# STM32WBA52 register map
File version: 1.3
CPU: CM33 r0p1, little endian, MPU, FPU, 4 interrupt priority bits
Registers are 32-bit, read-write, reset 0x0 unless marked. A register's access mark holds for its fields unless they carry their own. Offsets are from the block's base; [hi:lo] are bit positions; {n}, {i} and the like mark numbered series.

## DBGMCU — DBGMCU address block description
Base 0xE0044000
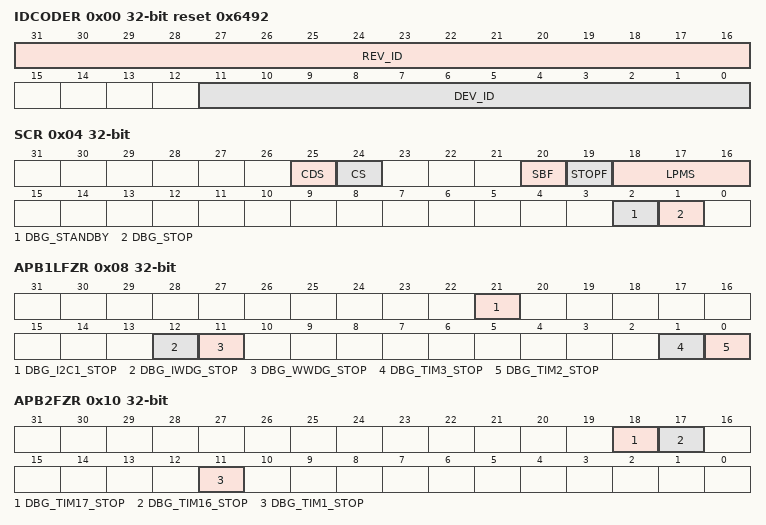
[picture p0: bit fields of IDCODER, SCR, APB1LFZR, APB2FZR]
0x00 IDCODER ro reset 0x6492 (reset mask 0xFFFF) — DBGMCU identity code register
  [31:16] REV_ID — Revision ID
  [11:0] DEV_ID — Device ID
0x04 SCR — DBGMCU status and configuration register
  [25] CDS ro — CPU DeepSleep
  [24] CS ro — CPU Sleep
  [20] SBF ro — Device Standby flag
  [19] STOPF ro — Device Stop flag
  [18:16] LPMS ro — Device low power mode selected 10x: Standby mode others reserved
  [2] DBG_STANDBY — Allows debug in Standby mode Write access can be protected by PWR_SECCFGR.LPMSEC. The CPU debug and DBGMCU clocks remain active and the HSI16 oscillator is used as system clock, the supply and SRAM memory content is maintained during Standby debug mode, allowing CPU debug capability. On exit from Standby mode, a standby reset is performed.
  [1] DBG_STOP — Allows debug in Stop mode Write access can be protected by PWR_SECCFGR.LPMSEC. The CPU debug and DBGMCU clocks remain active and the HSI16 oscillators is used as system clock during Stop debug mode, allowing CPU debug capability. On exit from Stop mode, the clock settings are set to the Stop mode exit state.
0x08 APB1LFZR — DBGMCU APB1L peripheral freeze register
  [21] DBG_I2C1_STOP — I2C1 SMBUS timeout stop in CPU debug Write access can be protected by GTZC_TZSC.I2C1SEC.
  [12] DBG_IWDG_STOP — IWDG stop in CPU debug Write access can be protected by GTZC_TZSC.IWDGSEC.
  [11] DBG_WWDG_STOP — WWDG stop in CPU debug Write access can be protected by GTZC_TZSC.WWDGSEC
  [1] DBG_TIM3_STOP — TIM3 stop in CPU debug Write access can be protected by GTZC_TZSC.TIM3SEC.
  [0] DBG_TIM2_STOP — TIM2 stop in CPU debug Write access can be protected by GTZC_TZSC.TIM2SEC.
0x0C APB1HFZR — DBGMCU APB1H peripheral freeze register
  [5] DBG_LPTIM2_STOP — LPTIM2 stop in CPU debug Write access can be protected by GTZC_TZSC.LPTIM2SEC.
0x10 APB2FZR — DBGMCU APB2 peripheral freeze register
  [18] DBG_TIM17_STOP — TIM17 stop in CPU debug Write access can be protected by GTZC_TZSC.TIM17SEC.
  [17] DBG_TIM16_STOP — TIM16 stop in CPU debug Write access can be protected by GTZC_TZSC.TIM16SEC.
  [11] DBG_TIM1_STOP — TIM1 stop in CPU debug Write access can be protected by GTZC_TZSC.TIM1SEC.
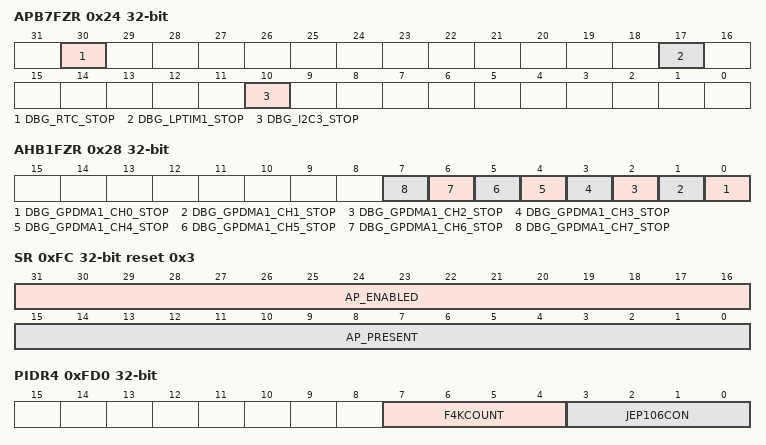
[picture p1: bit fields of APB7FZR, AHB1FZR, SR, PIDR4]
0x24 APB7FZR — DBGMCU APB7 peripheral freeze register
  [30] DBG_RTC_STOP — RTC stop in CPU debug Access can be protected by GTZC_TZSC.TIM17SEC. Can only be accessed secure when one or more features in the RTC or TAMP is/are secure.
  [17] DBG_LPTIM1_STOP — LPTIM1 stop in CPU debug Access can be protected by GTZC_TZSC.LPTIM1SEC.
  [10] DBG_I2C3_STOP — I2C3 stop in CPU debug Access can be protected by GTZC_TZSC.I2C3SEC.
0x28 AHB1FZR — DBGMCU AHB1 peripheral freeze register
  [n] DBG_GPDMA1_CH{n}_STOP (n=0..7) — GPDMA 1 channel {n} stop in CPU debug Write access can be protected by GPDMA_SECCFGR.SEC{n}.
0xFC SR ro reset 0x3 (reset mask 0xFFF0FFFF) — DBGMCU status register
  [31:16] AP_ENABLED — Bit n identifies whether access port APn is open (can be accessed via the debug port) or locked (debug access to the APn is blocked, except for DBGMCU access) Bit n = 0: APn locked (except for access to DBGMCU) Bit n = 1: APn enabled
  [15:0] AP_PRESENT — Bit n identifies whether access port APn is present in device Bit n = 0: APn absent Bit n = 1: APn present
0x100 DBG_AUTH_HOST wo reset not defined — DBGMCU debug host authentication register
  [31:0] AUTH_KEY — Device authentication key The device specific 64-bit authentication key (OEMn key) must be written to this register (in two successive 32-bit writes, least significant word first) to permit RDP regression. Writing a wrong key locks access to the device and prevent code execution from the Flash memory.
0x104 DBG_AUTH_DEVICE ro reset not defined — DBGMCU debug device authentication register
  [31:0] AUTH_ID — Device specific ID Device specific ID used for RDP regression.
0x7DC PNCR ro reset not defined — DBGMCU part number codification register
  [31:0] CODIFICATION — Part number codification
0xFD0 PIDR4 ro — DBGMCU CoreSight peripheral identity register 4
  [7:4] F4KCOUNT — Register file size
  [3:0] JEP106CON — JEP106 continuation code
0xFE0 PIDR0 ro — DBGMCU CoreSight peripheral identity register 0
  [7:0] PARTNUM — Part number bits [7:0]
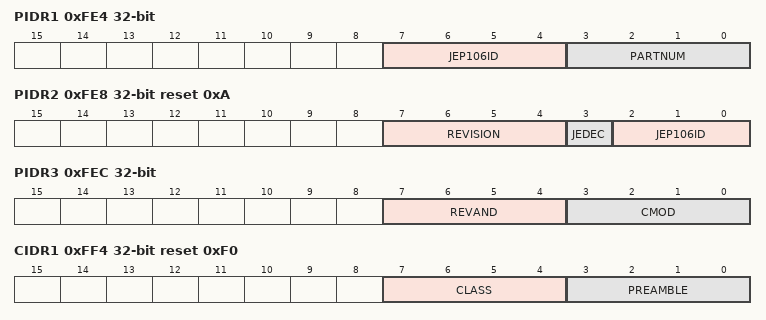
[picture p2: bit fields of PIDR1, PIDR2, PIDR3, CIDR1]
0xFE4 PIDR1 ro — DBGMCU CoreSight peripheral identity register 1
  [7:4] JEP106ID — JEP106 identity code bits [3:0]
  [3:0] PARTNUM — Part number bits [11:8]
0xFE8 PIDR2 ro reset 0xA — DBGMCU CoreSight peripheral identity register 2
  [7:4] REVISION — Component revision number
  [3] JEDEC — JEDEC assigned value
  [2:0] JEP106ID — JEP106 identity code bits [6:4]
0xFEC PIDR3 ro — DBGMCU CoreSight peripheral identity register 3
  [7:4] REVAND — Metal fix version
  [3:0] CMOD — Customer modified
0xFF0 CIDR0 ro reset 0xD — DBGMCU CoreSight component identity register 0
  [7:0] PREAMBLE — Component ID bits [7:0]
0xFF4 CIDR1 ro reset 0xF0 — DBGMCU CoreSight peripheral identity register 1
  [7:4] CLASS — Component ID bits [15:12] - component class
  [3:0] PREAMBLE — Component ID bits [11:8]
0xFF8 CIDR2 ro reset 0x5 — DBGMCU CoreSight component identity register 2
  [7:0] PREAMBLE — Component ID bits [23:16]
0xFFC CIDR3 ro reset 0xB1 — DBGMCU CoreSight component identity register 3
  [7:0] PREAMBLE — Component ID bits [31:24]
